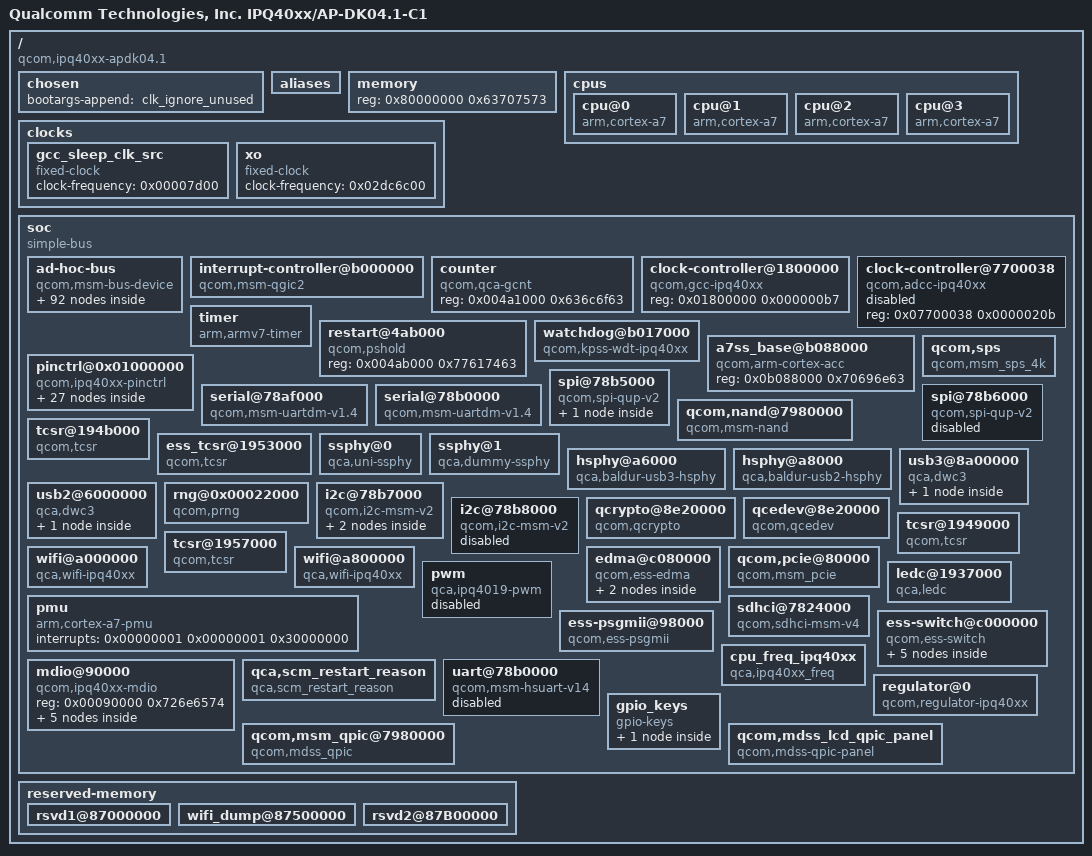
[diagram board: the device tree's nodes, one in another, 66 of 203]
/dts-v1/;
// magic:		0xd00dfeed
// totalsize:		0x93eb (37867)
// off_dt_struct:	0x38
// off_dt_strings:	0x8a74
// off_mem_rsvmap:	0x28
// version:		17
// last_comp_version:	16
// boot_cpuid_phys:	0x0
// size_dt_strings:	0x977
// size_dt_struct:	0x8a3c

/ {
    #address-cells = <0x00000001>;
    #size-cells = <0x00000001>;
    model = "Qualcomm Technologies, Inc. IPQ40xx/AP-DK04.1-C1";
    compatible = "qcom,ipq40xx-apdk04.1", "qcom,ipq40xx";
    interrupt-parent = <0x00000001>;
    chosen {
        bootargs-append = " clk_ignore_unused";
    };
    aliases {
        spi0 = "/soc/spi@78b5000";
        spi1 = "/soc/spi@78b6000";
        i2c0 = "/soc/i2c@78b7000";
        i2c1 = "/soc/i2c@78b8000";
        ethernet0 = "/soc/edma/gmac0";
        ethernet1 = "/soc/edma/gmac1";
    };
    memory {
        device_type = "memory";
        reg = <0x80000000 0x63707573>;
    };
    cpus {
        #address-cells = <0x00000001>;
        #size-cells = <0x00000000>;
        cpu@0 {
            device_type = "cpu";
            compatible = "arm,cortex-a7";
            enable-method = "qcom,arm-cortex-acc";
            reg = <0x00000000>;
            clocks = <0x00000002 0x0000009a>;
            clock-frequency = <0x00000000>;
        };
        cpu@1 {
            device_type = "cpu";
            compatible = "arm,cortex-a7";
            enable-method = "qcom,arm-cortex-acc";
            reg = <0x00000001>;
            clocks = <0x00000002 0x0000009a>;
            clock-frequency = <0x00000000>;
        };
        cpu@2 {
            device_type = "cpu";
            compatible = "arm,cortex-a7";
            enable-method = "qcom,arm-cortex-acc";
            reg = <0x00000002>;
            clocks = <0x00000002 0x0000009a>;
            clock-frequency = <0x00000000>;
        };
        cpu@3 {
            device_type = "cpu";
            compatible = "arm,cortex-a7";
            enable-method = "qcom,arm-cortex-acc";
            reg = <0x00000003>;
            clocks = <0x00000002 0x0000009a>;
            clock-frequency = <0x00000000>;
        };
    };
    clocks {
        gcc_sleep_clk_src {
            compatible = "fixed-clock";
            clock-frequency = <0x00007d00>;
            #clock-cells = <0x00000000>;
            linux,phandle = <0x00000047>;
            phandle = <0x00000047>;
        };
        xo {
            compatible = "fixed-clock";
            clock-frequency = <0x02dc6c00>;
            #clock-cells = <0x00000000>;
        };
    };
    soc {
        #address-cells = <0x00000001>;
        #size-cells = <0x00000001>;
        ranges;
        compatible = "simple-bus";
        ad-hoc-bus {
            compatible = "qcom,msm-bus-device";
            reg = <0x00580000 0x00000003 0x2d626173 0x00000000>;
            reg-names = "snoc-base", "pcnoc-base";
            fab-pcnoc {
                cell-id = <0x00001000>;
                label = "fab-pcnoc";
                qcom,fab-dev;
                qcom,base-name = "pcnoc-base";
                qcom,bypass-qos-prg;
                qcom,bus-type = <0x00000001>;
                qcom,qos-off = <0x00001000>;
                qcom,base-offset = <0x00000000>;
                clocks;
                linux,phandle = <0x00000004>;
                phandle = <0x00000004>;
            };
            fab-snoc {
                cell-id = <0x00000400>;
                label = "fab-snoc";
                qcom,fab-dev;
                qcom,base-name = "snoc-base";
                qcom,bypass-qos-prg;
                qcom,bus-type = <0x00000001>;
                qcom,qos-off = <0x00000080>;
                qcom,base-offset = <0x00000000>;
                clocks;
                linux,phandle = <0x00000031>;
                phandle = <0x00000031>;
            };
            mas-blsp-bam {
                cell-id = <0x0000006d>;
                label = "mas-blsp-bam";
                qcom,buswidth = <0x00000004>;
                qcom,ap-owned;
                qcom,connections = <0x00000003>;
                qcom,bus-dev = <0x00000004>;
                qcom,mas-rpm-id = <0x00000082>;
                qcom,blacklist = <0x00000005 0x00000009 0x0000000d 0x00000011 0x00000015 0x00000019 0x0000001d 0x00000021 0x00000025 0x00000029 0x6d61732d 0x00000003 0x00000003 0x75736232 0x00000004 0x00000000 0x00000199 0x000001a4 0x00000004 0x00000004 0x00000004 0x00000004 0x00000004 0x00000098 0x00000007 0x0000000b 0x0000000f 0x00000013 0x00000017 0x0000001b 0x0000001f 0x00000023 0x00000027 0x00000002 0x2d646d61 0x000000d6 0x000000de 0x30000000>;
            };
            mas-usb2-bam {
                cell-id = <0x0000006e>;
                label = "mas-usb2-bam";
                qcom,buswidth = <0x00000008>;
                qcom,ap-owned;
                qcom,qport = <0x0000000f>;
                qcom,qos-mode = "fixed";
                qcom,connections = <0x0000002b>;
                qcom,prio1 = <0x00000001>;
                qcom,prio0 = <0x00000001>;
                qcom,bus-dev = <0x00000004>;
                qcom,mas-rpm-id = <0x00000083>;
                qcom,blacklist = <0x00000005 0x00000009 0x0000000d 0x00000011 0x00000015 0x00000019 0x0000001d 0x00000021 0x00000025 0x00000029 0x6d61732d 0x00000003 0x00000003 0x61647373 0x00000004 0x00000000 0x0000015c 0x0000016d 0x0000017a 0x0000018a 0x00000008 0x0000000c 0x00000010 0x00000014 0x00000018 0x0000001c 0x00000020 0x00000024 0x00000028 0x00000001 0x31000000 0x00000070 0x6d61732d 0x00000003 0x00000003 0x00000004 0x00000004 0x00000004>;
            };
            mas-adss-dma0 {
                cell-id = <0x0000006f>;
                label = "mas-adss-dma0";
                qcom,buswidth = <0x00000004>;
                qcom,ap-owned;
                qcom,connections = <0x0000002c>;
                qcom,bus-dev = <0x00000004>;
                qcom,mas-rpm-id = <0x00000084>;
                qcom,blacklist = <0x00000005 0x00000009 0x0000000d 0x00000011 0x00000015 0x00000019 0x0000001d 0x00000021 0x00000025 0x00000029 0x6d61732d 0x00000003 0x00000003 0x61647373 0x00000004 0x00000000 0x0000015c 0x0000016d 0x0000017a 0x0000018a 0x00000008 0x0000000c 0x00000010 0x00000014 0x00000018 0x0000001c 0x00000020 0x00000024 0x00000028 0x00000001 0x32000000 0x00000071 0x6d61732d 0x00000003 0x00000003 0x00000004 0x00000004 0x00000004>;
            };
            mas-adss-dma1 {
                cell-id = <0x00000070>;
                label = "mas-adss-dma1";
                qcom,buswidth = <0x00000004>;
                qcom,ap-owned;
                qcom,connections = <0x0000002c>;
                qcom,bus-dev = <0x00000004>;
                qcom,mas-rpm-id = <0x00000085>;
                qcom,blacklist = <0x00000005 0x00000009 0x0000000d 0x00000011 0x00000015 0x00000019 0x0000001d 0x00000021 0x00000025 0x00000029 0x6d61732d 0x00000003 0x00000003 0x61647373 0x00000004 0x00000000 0x0000015c 0x0000016d 0x0000017a 0x0000018a 0x00000008 0x0000000c 0x00000010 0x00000014 0x00000018 0x0000001c 0x00000020 0x00000024 0x00000028 0x00000001 0x33000000 0x00000072 0x6d61732d 0x00000003 0x00000003 0x00000004 0x00000004 0x00000004>;
            };
            mas-adss-dma2 {
                cell-id = <0x00000071>;
                label = "mas-adss-dma2";
                qcom,buswidth = <0x00000004>;
                qcom,ap-owned;
                qcom,connections = <0x0000002c>;
                qcom,bus-dev = <0x00000004>;
                qcom,mas-rpm-id = <0x00000086>;
                qcom,blacklist = <0x00000005 0x00000009 0x0000000d 0x00000011 0x00000015 0x00000019 0x0000001d 0x00000021 0x00000025 0x00000029 0x6d61732d 0x00000003 0x00000003 0x61647373 0x00000004 0x00000000 0x0000015c 0x0000016d 0x0000017a 0x0000018a 0x00000008 0x0000000c 0x00000010 0x00000014 0x00000018 0x0000001c 0x00000020 0x00000024 0x00000028 0x00000001 0x00000000 0x00000073 0x6d61732d 0x00000003 0x00000003 0x00000004 0x00000004 0x00000004>;
            };
            mas-adss-dma3 {
                cell-id = <0x00000072>;
                label = "mas-adss-dma3";
                qcom,buswidth = <0x00000004>;
                qcom,ap-owned;
                qcom,connections = <0x0000002c>;
                qcom,bus-dev = <0x00000004>;
                qcom,mas-rpm-id = <0x00000087>;
                qcom,blacklist = <0x00000005 0x00000009 0x0000000d 0x00000011 0x00000015 0x00000019 0x0000001d 0x00000021 0x00000025 0x00000029 0x6d61732d 0x00000003 0x00000003 0x71706963 0x00000004 0x00000000 0x0000015c 0x0000016d 0x0000017a 0x0000018a 0x00000008 0x0000000c 0x00000010 0x00000014 0x00000018 0x0000001c 0x00000020 0x00000024 0x00000028 0x00000001 0x00000003 0x00000003 0x7370646d 0x00000140 0x0000014e 0x00000003 0x00000004 0x00000032>;
            };
            mas-qpic-bam {
                cell-id = <0x00000073>;
                label = "mas-qpic-bam";
                qcom,buswidth = <0x00000004>;
                qcom,ap-owned;
                qcom,connections = <0x00000003>;
                qcom,bus-dev = <0x00000004>;
                qcom,mas-rpm-id = <0x00000088>;
                qcom,blacklist = <0x00000005 0x00000009 0x0000000d 0x00000011 0x00000015 0x00000019 0x0000001d 0x00000021 0x00000025 0x00000029 0x6d61732d 0x00000004 0x00000009 0x00000000 0x00000004 0x00000003 0x00000003 0x00000003 0x00000003 0x00000006 0x0000000a 0x0000000e 0x00000012 0x00000016 0x0000001a 0x0000001e 0x00000022 0x00000026 0x0000002a 0x70636e6f 0x00000004 0x0000000e 0x632d6366 0x00000140 0x0000014e 0x00000026 0x00000004 0x00000054>;
            };
            mas-spdm {
                cell-id = <0x00000024>;
                label = "mas-spdm";
                qcom,buswidth = <0x00000004>;
                qcom,ap-owned;
                qcom,connections = <0x00000003>;
                qcom,bus-dev = <0x00000004>;
                qcom,mas-rpm-id = <0x00000032>;
                qcom,blacklist = <0x00000005 0x00000009 0x0000000d 0x00000011 0x00000015 0x00000019 0x0000001d 0x00000021 0x00000025 0x00000029 0x6d61732d 0x00000003 0x00000003 0x70636e6f 0x00000004 0x00000000 0x0000015c 0x0000016d 0x0000017a 0x6d61732d 0x000000d6 0x000000de 0x00000004 0x00000000 0x0000015c 0x00000004 0x00000004 0x00000001 0x00000000 0x00000074 0x6d61732d 0x00000003 0x00000003 0x00000004 0x00000006 0x00000003 0x00000003 0x00000003>;
            };
            mas-pcnoc-cfg {
                cell-id = <0x00000058>;
                label = "mas-pcnoc-cfg";
                qcom,buswidth = <0x00000004>;
                qcom,ap-owned;
                qcom,connections = <0x00000026>;
                qcom,bus-dev = <0x00000004>;
                qcom,mas-rpm-id = <0x00000054>;
            };
            mas-tic {
                cell-id = <0x0000004d>;
                label = "mas-tic";
                qcom,buswidth = <0x00000004>;
                qcom,ap-owned;
                qcom,connections = <0x0000002d 0x0000016d>;
                qcom,bus-dev = <0x00000004>;
                qcom,mas-rpm-id = <0x00000033>;
            };
            mas-sdcc-bam {
                cell-id = <0x00000074>;
                label = "mas-sdcc-bam";
                qcom,buswidth = <0x00000008>;
                qcom,ap-owned;
                qcom,qport = <0x0000000e>;
                qcom,qos-mode = "fixed";
                qcom,connections = <0x0000002b>;
                qcom,prio1 = <0x00000000>;
                qcom,prio0 = <0x00000000>;
                qcom,bus-dev = <0x00000004>;
                qcom,mas-rpm-id = <0x00000089>;
                qcom,blacklist = <0x00000005 0x00000009 0x0000000d 0x00000011 0x00000015 0x00000019 0x0000001d 0x00000021 0x00000025 0x00000029 0x6d61732d 0x00000003 0x00000003 0x736e6f63 0x00000004 0x00000000 0x00000199 0x000001a4 0x00000004 0x00000004 0x00000004 0x00000004 0x00000004 0x00000001 0x00000000 0x0000004c 0x6d61732d 0x00000003 0x00000003 0x00000008 0x00000003 0x00000003 0x00000002 0x2d736e6f 0x000000d6 0x000000de 0x63000000 0x00000010>;
            };
            mas-snoc-pcnoc {
                cell-id = <0x00002739>;
                label = "mas-snoc-pcnoc";
                qcom,buswidth = <0x00000004>;
                qcom,ap-owned;
                qcom,qport = <0x00000010>;
                qcom,qos-mode = "fixed";
                qcom,connections = <0x0000002d>;
                qcom,prio1 = <0x00000000>;
                qcom,prio0 = <0x00000000>;
                qcom,bus-dev = <0x00000004>;
                qcom,mas-rpm-id = <0x0000004d>;
            };
            mas-qdss-dap {
                cell-id = <0x0000004c>;
                label = "mas-qdss-dap";
                qcom,buswidth = <0x00000004>;
                qcom,ap-owned;
                qcom,connections = <0x0000002d 0x0000016d>;
                qcom,bus-dev = <0x00000004>;
                qcom,mas-rpm-id = <0x00000031>;
            };
            mas-ddrc-snoc {
                cell-id = <0x00000075>;
                label = "mas-ddrc-snoc";
                qcom,buswidth = <0x00000010>;
                qcom,ap-owned;
                qcom,connections = <0x0000002e 0x00000004 0x00000004>;
                qcom,bus-dev = <0x00000031>;
                qcom,mas-rpm-id = <0x0000008a>;
                qcom,blacklist = <0x00000032 0x6d61732d>;
            };
            mas-wss-0 {
                cell-id = <0x00000076>;
                label = "mas-wss-0";
                qcom,buswidth = <0x00000004>;
                qcom,ap-owned;
                qcom,qport = <0x0000001a>;
                qcom,qos-mode = "fixed";
                qcom,connections = <0x0000002e 0x000001b2>;
                qcom,prio1 = <0x00000000>;
                qcom,prio0 = <0x00000000>;
                qcom,bus-dev = <0x00000031>;
                qcom,mas-rpm-id = <0x0000008b>;
                qcom,blacklist = <0x00000034 0x00000037 0x00000001 0x00000003 0x00000003 0x7773732d 0x00000140>;
            };
            mas-wss-1 {
                cell-id = <0x00000077>;
                label = "mas-wss-1";
                qcom,buswidth = <0x00000004>;
                qcom,ap-owned;
                qcom,qport = <0x0000001b>;
                qcom,qos-mode = "fixed";
                qcom,connections = <0x0000002e 0x000001b2>;
                qcom,prio1 = <0x00000000>;
                qcom,prio0 = <0x00000000>;
                qcom,bus-dev = <0x00000031>;
                qcom,mas-rpm-id = <0x0000008c>;
                qcom,blacklist = <0x00000034 0x00000037 0x00000001 0x00000003 0x00000003 0x63727970 0x00000140>;
            };
            mas-crypto {
                cell-id = <0x0000002f>;
                label = "mas-crypto";
                qcom,buswidth = <0x00000008>;
                qcom,ap-owned;
                qcom,qport = <0x00000005>;
                qcom,qos-mode = "fixed";
                qcom,connections = <0x0000002e 0x00000004 0x00000004>;
                qcom,prio1 = <0x00000000>;
                qcom,prio0 = <0x00000000>;
                qcom,bus-dev = <0x00000031>;
                qcom,mas-rpm-id = <0x00000017>;
                qcom,blacklist = <0x00000034 0x0000003a 0x00000001 0x00000004 0x00000008 0x00000003 0x00000003>;
            };
            mas-ess {
                cell-id = <0x00000078>;
                label = "mas-ess";
                qcom,buswidth = <0x00000008>;
                qcom,ap-owned;
                qcom,qport = <0x0000002c>;
                qcom,qos-mode = "fixed";
                qcom,connections = <0x0000002e 0x000001b2>;
                qcom,prio1 = <0x00000000>;
                qcom,prio0 = <0x00000000>;
                qcom,bus-dev = <0x00000031>;
                qcom,mas-rpm-id = <0x0000008d>;
                qcom,blacklist = <0x00000034 0x0000003a 0x00000033 0x70636965 0x000000d6 0x000000de 0x00000003 0x00000003 0x00000004>;
            };
            mas-pcie {
                cell-id = <0x0000002d>;
                label = "mas-pcie";
                qcom,buswidth = <0x00000008>;
                qcom,ap-owned;
                qcom,qport = <0x00000006>;
                qcom,qos-mode = "fixed";
                qcom,connections = <0x0000002e 0x000001b2>;
                qcom,prio1 = <0x00000000>;
                qcom,prio0 = <0x00000000>;
                qcom,bus-dev = <0x00000031>;
                qcom,mas-rpm-id = <0x0000008e>;
                qcom,blacklist = <0x00000034 0x00000036 0x00000002 0x00000000 0x0000003d 0x6d61732d 0x00000004 0x00000000>;
            };
            mas-usb3 {
                cell-id = <0x0000003d>;
                label = "mas-usb3";
                qcom,buswidth = <0x00000008>;
                qcom,ap-owned;
                qcom,qport = <0x00000007>;
                qcom,qos-mode = "fixed";
                qcom,connections = <0x0000002e 0x000001b2>;
                qcom,prio1 = <0x00000000>;
                qcom,prio0 = <0x00000000>;
                qcom,bus-dev = <0x00000031>;
                qcom,mas-rpm-id = <0x00000020>;
                qcom,blacklist = <0x00000034 0x0000003a 0x00000033 0x71647373 0x00000004 0x0000000d 0x2d657472 0x00000140 0x0000014e>;
            };
            mas-qdss-etr {
                cell-id = <0x0000003c>;
                label = "mas-qdss-etr";
                qcom,buswidth = <0x00000008>;
                qcom,ap-owned;
                qcom,qport = <0x00000220>;
                qcom,qos-mode = "fixed";
                qcom,connections = <0x0000003b>;
                qcom,prio1 = <0x00000000>;
                qcom,prio0 = <0x00000000>;
                qcom,bus-dev = <0x00000031>;
                qcom,mas-rpm-id = <0x0000001f>;
                qcom,blacklist = <0x00000034 0x0000003a 0x00000033 0x71647373 0x00000004 0x00000010 0x2d62616d 0x00000140 0x0000014e>;
            };
            mas-qdss-bamndp {
                cell-id = <0x00000079>;
                label = "mas-qdss-bamndp";
                qcom,buswidth = <0x00000004>;
                qcom,ap-owned;
                qcom,qport = <0x00000240>;
                qcom,qos-mode = "fixed";
                qcom,connections = <0x0000003b>;
                qcom,prio1 = <0x00000000>;
                qcom,prio0 = <0x00000000>;
                qcom,bus-dev = <0x00000031>;
                qcom,mas-rpm-id = <0x0000008f>;
                qcom,blacklist = <0x00000034 0x0000003a 0x00000033 0x70636e6f 0x00000004 0x0000000f 0x632d736e 0x00000140 0x0000014e>;
            };
            mas-pcnoc-snoc {
                cell-id = <0x0000271a>;
                label = "mas-pcnoc-snoc";
                qcom,buswidth = <0x00000004>;
                qcom,ap-owned;
                qcom,qport = <0x00000180>;
                qcom,qos-mode = "fixed";
                qcom,connections = <0x0000002e 0x00000004 0x00000004>;
                qcom,prio1 = <0x00000000>;
                qcom,prio0 = <0x00000000>;
                qcom,bus-dev = <0x00000031>;
                qcom,mas-rpm-id = <0x0000001d>;
                qcom,blacklist = <0x00000033>;
            };
            mas-snoc-cfg {
                cell-id = <0x0000007a>;
                label = "mas-snoc-cfg";
                qcom,buswidth = <0x00000004>;
                qcom,ap-owned;
                qcom,connections = <0x00000033>;
                qcom,bus-dev = <0x00000031>;
                qcom,mas-rpm-id = <0x00000090>;
            };
            pcnoc-m-0 {
                cell-id = <0x0000271e>;
                label = "pcnoc-m-0";
                qcom,buswidth = <0x00000004>;
                qcom,ap-owned;
                qcom,qport = <0x0000000c>;
                qcom,qos-mode = "fixed";
                qcom,connections = <0x0000002b>;
                qcom,prio1 = <0x00000001>;
                qcom,prio0 = <0x00000001>;
                qcom,bus-dev = <0x00000004>;
                qcom,mas-rpm-id = <0x00000057>;
                qcom,slv-rpm-id = <0x00000074>;
                linux,phandle = <0x00000003>;
                phandle = <0x00000003>;
            };
            pcnoc-m-1 {
                cell-id = <0x0000271f>;
                label = "pcnoc-m-1";
                qcom,buswidth = <0x00000004>;
                qcom,ap-owned;
                qcom,qport = <0x0000000d>;
                qcom,qos-mode = "fixed";
                qcom,connections = <0x0000002b>;
                qcom,prio1 = <0x00000001>;
                qcom,prio0 = <0x00000001>;
                qcom,bus-dev = <0x00000004>;
                qcom,mas-rpm-id = <0x00000058>;
                qcom,slv-rpm-id = <0x00000075>;
                linux,phandle = <0x0000002c>;
                phandle = <0x0000002c>;
            };
            pcnoc-int-0 {
                cell-id = <0x0000271c>;
                label = "pcnoc-int-0";
                qcom,buswidth = <0x00000008>;
                qcom,ap-owned;
                qcom,connections = <0x0000003c 0x00000040 0x00000044 0x0000016d 0x0000017a 0x000001c8 0x000000b7 0x000000bd 0x70636e6f 0x00000004>;
                qcom,bus-dev = <0x00000004>;
                qcom,mas-rpm-id = <0x00000055>;
                qcom,slv-rpm-id = <0x00000072>;
                linux,phandle = <0x0000002d>;
                phandle = <0x0000002d>;
            };
            pcnoc-s-0 {
                cell-id = <0x00002722>;
                label = "pcnoc-s-0";
                qcom,buswidth = <0x00000004>;
                qcom,ap-owned;
                qcom,connections = <0x00000022 0x00000003 0x00000003 0x00000003>;
                qcom,bus-dev = <0x00000004>;
                qcom,mas-rpm-id = <0x00000059>;
                qcom,slv-rpm-id = <0x00000076>;
                linux,phandle = <0x0000003e>;
                phandle = <0x0000003e>;
            };
            pcnoc-s-1 {
                cell-id = <0x00002723>;
                label = "pcnoc-s-1";
                qcom,buswidth = <0x00000004>;
                qcom,ap-owned;
                qcom,connections = <0x00000019 0x00000004 0x00000004>;
                qcom,bus-dev = <0x00000004>;
                qcom,mas-rpm-id = <0x0000005a>;
                qcom,slv-rpm-id = <0x00000077>;
                linux,phandle = <0x0000003c>;
                phandle = <0x0000003c>;
            };
            pcnoc-s-2 {
                cell-id = <0x00002724>;
                label = "pcnoc-s-2";
                qcom,buswidth = <0x00000004>;
                qcom,ap-owned;
                qcom,connections = <0x0000001c 0x00000003 0x00000003 0x00000003>;
                qcom,bus-dev = <0x00000004>;
                qcom,mas-rpm-id = <0x0000005b>;
                qcom,slv-rpm-id = <0x00000078>;
                linux,phandle = <0x0000003d>;
                phandle = <0x0000003d>;
            };
            pcnoc-s-3 {
                cell-id = <0x00002725>;
                label = "pcnoc-s-3";
                qcom,buswidth = <0x00000004>;
                qcom,ap-owned;
                qcom,connections = <0x00000013 0x00000003 0x00000003 0x00000003>;
                qcom,bus-dev = <0x00000004>;
                qcom,mas-rpm-id = <0x0000005c>;
                qcom,slv-rpm-id = <0x00000079>;
                linux,phandle = <0x00000045>;
                phandle = <0x00000045>;
            };
            pcnoc-s-4 {
                cell-id = <0x00002726>;
                label = "pcnoc-s-4";
                qcom,buswidth = <0x00000004>;
                qcom,ap-owned;
                qcom,connections = <0x00000007 0x00000004 0x00000004>;
                qcom,bus-dev = <0x00000004>;
                qcom,mas-rpm-id = <0x0000005d>;
                qcom,slv-rpm-id = <0x0000007a>;
                linux,phandle = <0x0000003f>;
                phandle = <0x0000003f>;
            };
            pcnoc-s-5 {
                cell-id = <0x0000273f>;
                label = "pcnoc-s-5";
                qcom,buswidth = <0x00000004>;
                qcom,ap-owned;
                qcom,connections = <0x00000020 0x00000003 0x00000003 0x00000003>;
                qcom,bus-dev = <0x00000004>;
                qcom,mas-rpm-id = <0x00000081>;
                qcom,slv-rpm-id = <0x000000bd>;
                linux,phandle = <0x00000040>;
                phandle = <0x00000040>;
            };
            pcnoc-s-6 {
                cell-id = <0x00002740>;
                label = "pcnoc-s-6";
                qcom,buswidth = <0x00000004>;
                qcom,ap-owned;
                qcom,connections = <0x0000000b 0x0000000a 0x00000004 0x0000005e 0x0000007b>;
                qcom,bus-dev = <0x00000004>;
                qcom,mas-rpm-id = <0x0000005e>;
                qcom,slv-rpm-id = <0x0000007b>;
                linux,phandle = <0x00000041>;
                phandle = <0x00000041>;
            };
            pcnoc-s-7 {
                cell-id = <0x00002752>;
                label = "pcnoc-s-7";
                qcom,buswidth = <0x00000004>;
                qcom,ap-owned;
                qcom,connections = <0x0000000f 0x00000004 0x00000004>;
                qcom,bus-dev = <0x00000004>;
                qcom,mas-rpm-id = <0x0000005f>;
                qcom,slv-rpm-id = <0x0000007c>;
                linux,phandle = <0x00000042>;
                phandle = <0x00000042>;
            };
            pcnoc-s-8 {
                cell-id = <0x00002727>;
                label = "pcnoc-s-8";
                qcom,buswidth = <0x00000004>;
                qcom,ap-owned;
                qcom,connections = <0x00000029 0x00000004 0x00000004>;
                qcom,bus-dev = <0x00000004>;
                qcom,mas-rpm-id = <0x00000060>;
                qcom,slv-rpm-id = <0x0000007d>;
                linux,phandle = <0x00000043>;
                phandle = <0x00000043>;
            };
            pcnoc-s-9 {
                cell-id = <0x00002728>;
                label = "pcnoc-s-9";
                qcom,buswidth = <0x00000004>;
                qcom,ap-owned;
                qcom,connections = <0x00000009 0x00000003 0x00000003 0x00000003>;
                qcom,bus-dev = <0x00000004>;
                qcom,mas-rpm-id = <0x00000061>;
                qcom,slv-rpm-id = <0x0000007e>;
                linux,phandle = <0x00000044>;
                phandle = <0x00000044>;
            };
            snoc-int-0 {
                cell-id = <0x00002714>;
                label = "snoc-int-0";
                qcom,buswidth = <0x00000008>;
                qcom,ap-owned;
                qcom,connections = <0x00000046 0x0000016d>;
                qcom,bus-dev = <0x00000031>;
                qcom,mas-rpm-id = <0x00000063>;
                qcom,slv-rpm-id = <0x00000082>;
                linux,phandle = <0x0000002e>;
                phandle = <0x0000002e>;
            };
            snoc-int-1 {
                cell-id = <0x00002715>;
                label = "snoc-int-1";
                qcom,buswidth = <0x00000008>;
                qcom,ap-owned;
                qcom,connections = <0x00000038 0x00000036 0x0000016d 0x0000017a 0x000001c8 0x000000b7>;
                qcom,bus-dev = <0x00000031>;
                qcom,mas-rpm-id = <0x00000064>;
                qcom,slv-rpm-id = <0x00000083>;
                linux,phandle = <0x0000002f>;
                phandle = <0x0000002f>;
            };
            qdss-int {
                cell-id = <0x00002719>;
                label = "qdss-int";
                qcom,buswidth = <0x00000008>;
                qcom,ap-owned;
                qcom,connections = <0x0000002e 0x0000016d>;
                qcom,bus-dev = <0x00000031>;
                qcom,mas-rpm-id = <0x00000062>;
                qcom,slv-rpm-id = <0x00000080>;
                linux,phandle = <0x0000003b>;
                phandle = <0x0000003b>;
            };
            slv-clk-ctl {
                cell-id = <0x0000026c>;
                label = "slv-clk-ctl";
                qcom,buswidth = <0x00000004>;
                qcom,ap-owned;
                qcom,bus-dev = <0x00000004>;
                qcom,slv-rpm-id = <0x0000002f>;
                linux,phandle = <0x00000022>;
                phandle = <0x00000022>;
            };
            slv-security {
                cell-id = <0x0000026e>;
                label = "slv-security";
                qcom,buswidth = <0x00000004>;
                qcom,ap-owned;
                qcom,bus-dev = <0x00000004>;
                qcom,slv-rpm-id = <0x00000031>;
                linux,phandle = <0x0000001b>;
                phandle = <0x0000001b>;
            };
            slv-tcsr {
                cell-id = <0x0000026f>;
                label = "slv-tcsr";
                qcom,buswidth = <0x00000004>;
                qcom,ap-owned;
                qcom,bus-dev = <0x00000004>;
                qcom,slv-rpm-id = <0x00000032>;
                linux,phandle = <0x00000005>;
                phandle = <0x00000005>;
            };
            slv-tlmm {
                cell-id = <0x00000270>;
                label = "slv-tlmm";
                qcom,buswidth = <0x00000004>;
                qcom,ap-owned;
                qcom,bus-dev = <0x00000004>;
                qcom,slv-rpm-id = <0x00000033>;
                linux,phandle = <0x00000017>;
                phandle = <0x00000017>;
            };
            slv-imem-cfg {
                cell-id = <0x00000273>;
                label = "slv-imem-cfg";
                qcom,buswidth = <0x00000004>;
                qcom,ap-owned;
                qcom,bus-dev = <0x00000004>;
                qcom,slv-rpm-id = <0x00000036>;
                linux,phandle = <0x00000010>;
                phandle = <0x00000010>;
            };
            slv-prng {
                cell-id = <0x0000026a>;
                label = "slv-prng";
                qcom,buswidth = <0x00000004>;
                qcom,ap-owned;
                qcom,bus-dev = <0x00000004>;
                qcom,slv-rpm-id = <0x0000002c>;
                linux,phandle = <0x00000012>;
                phandle = <0x00000012>;
            };
            slv-prng-apu-cfg {
                cell-id = <0x000002cc>;
                label = "slv-prng-apu-cfg";
                qcom,buswidth = <0x00000004>;
                qcom,ap-owned;
                qcom,bus-dev = <0x00000004>;
                qcom,slv-rpm-id = <0x000000be>;
                linux,phandle = <0x00000019>;
                phandle = <0x00000019>;
            };
            slv-boot-rom {
                cell-id = <0x00000276>;
                label = "slv-boot-rom";
                qcom,buswidth = <0x00000004>;
                qcom,ap-owned;
                qcom,bus-dev = <0x00000004>;
                qcom,slv-rpm-id = <0x00000039>;
                linux,phandle = <0x0000001a>;
                phandle = <0x0000001a>;
            };
            slv-spdm {
                cell-id = <0x00000279>;
                label = "slv-spdm";
                qcom,buswidth = <0x00000004>;
                qcom,ap-owned;
                qcom,bus-dev = <0x00000004>;
                qcom,slv-rpm-id = <0x0000003c>;
                linux,phandle = <0x0000001c>;
                phandle = <0x0000001c>;
            };
            slv-pcnoc-cfg {
                cell-id = <0x00000281>;
                label = "slv-pcnoc-cfg";
                qcom,buswidth = <0x00000004>;
                qcom,ap-owned;
                qcom,bus-dev = <0x00000004>;
                qcom,slv-rpm-id = <0x00000045>;
                linux,phandle = <0x0000000e>;
                phandle = <0x0000000e>;
            };
            slv-pcnoc-mpu-cfg {
                cell-id = <0x000002cd>;
                label = "slv-pcnoc-mpu-cfg";
                qcom,buswidth = <0x00000004>;
                qcom,ap-owned;
                qcom,bus-dev = <0x00000004>;
                qcom,slv-rpm-id = <0x000000bf>;
                linux,phandle = <0x0000001d>;
                phandle = <0x0000001d>;
            };
            slv-gcnt {
                cell-id = <0x000002ce>;
                label = "slv-gcnt";
                qcom,buswidth = <0x00000004>;
                qcom,ap-owned;
                qcom,bus-dev = <0x00000004>;
                qcom,slv-rpm-id = <0x000000c0>;
                linux,phandle = <0x00000016>;
                phandle = <0x00000016>;
            };
            slv-qdss-cfg {
                cell-id = <0x0000027b>;
                label = "slv-qdss-cfg";
                qcom,buswidth = <0x00000004>;
                qcom,ap-owned;
                qcom,bus-dev = <0x00000004>;
                qcom,slv-rpm-id = <0x0000003f>;
                linux,phandle = <0x00000013>;
                phandle = <0x00000013>;
            };
            slv-snoc-cfg {
                cell-id = <0x00000282>;
                label = "slv-snoc-cfg";
                qcom,buswidth = <0x00000004>;
                qcom,ap-owned;
                qcom,bus-dev = <0x00000004>;
                qcom,slv-rpm-id = <0x00000046>;
                linux,phandle = <0x0000002a>;
                phandle = <0x0000002a>;
            };
            slv-snoc-mpu-cfg {
                cell-id = <0x0000027e>;
                label = "slv-snoc-mpu-cfg";
                qcom,buswidth = <0x00000004>;
                qcom,ap-owned;
                qcom,bus-dev = <0x00000004>;
                qcom,slv-rpm-id = <0x00000043>;
                linux,phandle = <0x00000027>;
                phandle = <0x00000027>;
            };
            slv-adss-cfg {
                cell-id = <0x000002cf>;
                label = "slv-adss-cfg";
                qcom,buswidth = <0x00000004>;
                qcom,ap-owned;
                qcom,bus-dev = <0x00000004>;
                qcom,slv-rpm-id = <0x000000c1>;
                linux,phandle = <0x00000007>;
                phandle = <0x00000007>;
            };
            slv-adss-apu {
                cell-id = <0x000002d0>;
                label = "slv-adss-apu";
                qcom,buswidth = <0x00000004>;
                qcom,ap-owned;
                qcom,bus-dev = <0x00000004>;
                qcom,slv-rpm-id = <0x000000c2>;
                linux,phandle = <0x00000023>;
                phandle = <0x00000023>;
            };
            slv-adss-vmidmt-cfg {
                cell-id = <0x000002d0>;
                label = "slv-adss-vmidmt-cfg";
                qcom,buswidth = <0x00000004>;
                qcom,ap-owned;
                qcom,bus-dev = <0x00000004>;
                qcom,slv-rpm-id = <0x000000c3>;
                linux,phandle = <0x00000021>;
                phandle = <0x00000021>;
            };
            slv-qhss-apu-cfg {
                cell-id = <0x000002d1>;
                label = "slv-qhss-apu-cfg";
                qcom,buswidth = <0x00000004>;
                qcom,ap-owned;
                qcom,bus-dev = <0x00000004>;
                qcom,slv-rpm-id = <0x000000c4>;
                linux,phandle = <0x00000020>;
                phandle = <0x00000020>;
            };
            slv-mdio {
                cell-id = <0x000002d2>;
                label = "slv-mdio";
                qcom,buswidth = <0x00000004>;
                qcom,ap-owned;
                qcom,bus-dev = <0x00000004>;
                qcom,slv-rpm-id = <0x000000c5>;
                linux,phandle = <0x00000006>;
                phandle = <0x00000006>;
            };
            slv-fephy-cfg {
                cell-id = <0x000002d3>;
                label = "slv-fephy-cfg";
                qcom,buswidth = <0x00000004>;
                qcom,ap-owned;
                qcom,bus-dev = <0x00000004>;
                qcom,slv-rpm-id = <0x000000c6>;
                linux,phandle = <0x00000008>;
                phandle = <0x00000008>;
            };
            slv-srif {
                cell-id = <0x000002d4>;
                label = "slv-srif";
                qcom,buswidth = <0x00000004>;
                qcom,ap-owned;
                qcom,bus-dev = <0x00000004>;
                qcom,slv-rpm-id = <0x000000c7>;
                linux,phandle = <0x00000011>;
                phandle = <0x00000011>;
            };
            slv-ddrc-cfg {
                cell-id = <0x000002db>;
                label = "slv-ddrc-cfg";
                qcom,buswidth = <0x00000004>;
                qcom,ap-owned;
                qcom,bus-dev = <0x00000004>;
                qcom,slv-rpm-id = <0x000000c8>;
                linux,phandle = <0x0000000d>;
                phandle = <0x0000000d>;
            };
            slv-ddrc-apu-cfg {
                cell-id = <0x000002dc>;
                label = "slv-ddrc-apu-cfg";
                qcom,buswidth = <0x00000004>;
                qcom,ap-owned;
                qcom,bus-dev = <0x00000004>;
                qcom,slv-rpm-id = <0x000000c9>;
                linux,phandle = <0x00000015>;
                phandle = <0x00000015>;
            };
            slv-ddrc-mpu0-cfg {
                cell-id = <0x000002dd>;
                label = "slv-ddrc-mpu0-cfg";
                qcom,buswidth = <0x00000004>;
                qcom,ap-owned;
                qcom,bus-dev = <0x00000004>;
                qcom,slv-rpm-id = <0x000000ca>;
                linux,phandle = <0x0000000b>;
                phandle = <0x0000000b>;
            };
            slv-ddrc-mpu1-cfg {
                cell-id = <0x000002de>;
                label = "slv-ddrc-mpu1-cfg";
                qcom,buswidth = <0x00000004>;
                qcom,ap-owned;
                qcom,bus-dev = <0x00000004>;
                qcom,slv-rpm-id = <0x000000cb>;
                linux,phandle = <0x0000000a>;
                phandle = <0x0000000a>;
            };
            slv-ddrc-mpu2-cfg {
                cell-id = <0x000002de>;
                label = "slv-ddrc-mpu2-cfg";
                qcom,buswidth = <0x00000004>;
                qcom,ap-owned;
                qcom,bus-dev = <0x00000004>;
                qcom,slv-rpm-id = <0x000000d2>;
                linux,phandle = <0x0000001e>;
                phandle = <0x0000001e>;
            };
            slv-ess-vmidmt-cfg {
                cell-id = <0x000002df>;
                label = "slv-ess-vmidmt-cfg";
                qcom,buswidth = <0x00000004>;
                qcom,ap-owned;
                qcom,bus-dev = <0x00000004>;
                qcom,slv-rpm-id = <0x000000d3>;
                linux,phandle = <0x0000001f>;
                phandle = <0x0000001f>;
            };
            slv-ess-apu-cfg {
                cell-id = <0x000002e0>;
                label = "slv-ess-apu-cfg";
                qcom,buswidth = <0x00000004>;
                qcom,ap-owned;
                qcom,bus-dev = <0x00000004>;
                qcom,slv-rpm-id = <0x000000d4>;
                linux,phandle = <0x0000000f>;
                phandle = <0x0000000f>;
            };
            slv-usb2-cfg {
                cell-id = <0x000002e1>;
                label = "slv-usb2-cfg";
                qcom,buswidth = <0x00000004>;
                qcom,ap-owned;
                qcom,bus-dev = <0x00000004>;
                qcom,slv-rpm-id = <0x000000d5>;
                linux,phandle = <0x00000025>;
                phandle = <0x00000025>;
            };
            slv-blsp-cfg {
                cell-id = <0x000002e2>;
                label = "slv-blsp-cfg";
                qcom,buswidth = <0x00000004>;
                qcom,ap-owned;
                qcom,bus-dev = <0x00000004>;
                qcom,slv-rpm-id = <0x000000d6>;
                linux,phandle = <0x00000024>;
                phandle = <0x00000024>;
            };
            slv-qpic-cfg {
                cell-id = <0x000002e3>;
                label = "slv-qpic-cfg";
                qcom,buswidth = <0x00000004>;
                qcom,ap-owned;
                qcom,bus-dev = <0x00000004>;
                qcom,slv-rpm-id = <0x000000d7>;
                linux,phandle = <0x0000000c>;
                phandle = <0x0000000c>;
            };
            slv-sdcc-cfg {
                cell-id = <0x000002e4>;
                label = "slv-sdcc-cfg";
                qcom,buswidth = <0x00000004>;
                qcom,ap-owned;
                qcom,bus-dev = <0x00000004>;
                qcom,slv-rpm-id = <0x000000d8>;
                linux,phandle = <0x00000029>;
                phandle = <0x00000029>;
            };
            slv-wss0-vmidmt-cfg {
                cell-id = <0x000002e5>;
                label = "slv-wss0-vmidmt-cfg";
                qcom,buswidth = <0x00000004>;
                qcom,ap-owned;
                qcom,bus-dev = <0x00000004>;
                qcom,slv-rpm-id = <0x000000d9>;
                linux,phandle = <0x00000018>;
                phandle = <0x00000018>;
            };
            slv-wss0-apu-cfg {
                cell-id = <0x000002e6>;
                label = "slv-wss0-apu-cfg";
                qcom,buswidth = <0x00000004>;
                qcom,ap-owned;
                qcom,bus-dev = <0x00000004>;
                qcom,slv-rpm-id = <0x000000da>;
                linux,phandle = <0x00000014>;
                phandle = <0x00000014>;
            };
            slv-wss1-vmidmt-cfg {
                cell-id = <0x000002e7>;
                label = "slv-wss1-vmidmt-cfg";
                qcom,buswidth = <0x00000004>;
                qcom,ap-owned;
                qcom,bus-dev = <0x00000004>;
                qcom,slv-rpm-id = <0x000000db>;
                linux,phandle = <0x00000028>;
                phandle = <0x00000028>;
            };
            slv-wss1-apu-cfg {
                cell-id = <0x000002e8>;
                label = "slv-wss1-apu-cfg";
                qcom,buswidth = <0x00000004>;
                qcom,ap-owned;
                qcom,bus-dev = <0x00000004>;
                qcom,slv-rpm-id = <0x000000dc>;
                linux,phandle = <0x00000009>;
                phandle = <0x00000009>;
            };
            slv-pcnoc-snoc {
                cell-id = <0x0000271b>;
                label = "slv-pcnoc-snoc";
                qcom,buswidth = <0x00000004>;
                qcom,ap-owned;
                qcom,bus-dev = <0x00000004>;
                qcom,slv-rpm-id = <0x0000002d>;
                linux,phandle = <0x0000002b>;
                phandle = <0x0000002b>;
            };
            slv-srvc-pcnoc {
                cell-id = <0x000002e9>;
                label = "slv-srvc-pcnoc";
                qcom,buswidth = <0x00000004>;
                qcom,ap-owned;
                qcom,bus-dev = <0x00000004>;
                qcom,slv-rpm-id = <0x000000dd>;
                linux,phandle = <0x00000026>;
                phandle = <0x00000026>;
            };
            slv-snoc-ddrc-m1 {
                cell-id = <0x000002ea>;
                label = "slv-snoc-ddrc-m1";
                qcom,buswidth = <0x00000008>;
                qcom,ap-owned;
                qcom,bus-dev = <0x00000031>;
                qcom,slv-rpm-id = <0x000000de>;
                linux,phandle = <0x00000032>;
                phandle = <0x00000032>;
            };
            slv-a7ss {
                cell-id = <0x000002eb>;
                label = "slv-a7ss";
                qcom,buswidth = <0x00000004>;
                qcom,ap-owned;
                qcom,bus-dev = <0x00000031>;
                qcom,slv-rpm-id = <0x000000df>;
                linux,phandle = <0x00000039>;
                phandle = <0x00000039>;
            };
            slv-ocimem {
                cell-id = <0x00000249>;
                label = "slv-ocimem";
                qcom,buswidth = <0x00000008>;
                qcom,ap-owned;
                qcom,bus-dev = <0x00000031>;
                qcom,slv-rpm-id = <0x0000001a>;
                linux,phandle = <0x00000046>;
                phandle = <0x00000046>;
            };
            slv-wss0-cfg {
                cell-id = <0x000002ec>;
                label = "slv-wss0-cfg";
                qcom,buswidth = <0x00000004>;
                qcom,ap-owned;
                qcom,bus-dev = <0x00000031>;
                qcom,slv-rpm-id = <0x000000e0>;
                linux,phandle = <0x00000037>;
                phandle = <0x00000037>;
            };
            slv-wss1-cfg {
                cell-id = <0x000002ed>;
                label = "slv-wss1-cfg";
                qcom,buswidth = <0x00000004>;
                qcom,ap-owned;
                qcom,bus-dev = <0x00000031>;
                qcom,slv-rpm-id = <0x000000e1>;
                linux,phandle = <0x00000036>;
                phandle = <0x00000036>;
            };
            slv-pcie {
                cell-id = <0x000002ee>;
                label = "slv-pcie";
                qcom,buswidth = <0x00000008>;
                qcom,ap-owned;
                qcom,bus-dev = <0x00000031>;
                qcom,slv-rpm-id = <0x000000e2>;
                linux,phandle = <0x00000030>;
                phandle = <0x00000030>;
            };
            slv-usb3-cfg {
                cell-id = <0x000002ef>;
                label = "slv-usb3-cfg";
                qcom,buswidth = <0x00000004>;
                qcom,ap-owned;
                qcom,bus-dev = <0x00000031>;
                qcom,slv-rpm-id = <0x000000e3>;
                linux,phandle = <0x00000034>;
                phandle = <0x00000034>;
            };
            slv-crypto-cfg {
                cell-id = <0x000002f0>;
                label = "slv-crypto-cfg";
                qcom,buswidth = <0x00000004>;
                qcom,ap-owned;
                qcom,bus-dev = <0x00000031>;
                qcom,slv-rpm-id = <0x000000e4>;
                linux,phandle = <0x00000038>;
                phandle = <0x00000038>;
            };
            slv-ess-cfg {
                cell-id = <0x000002f1>;
                label = "slv-ess-cfg";
                qcom,buswidth = <0x00000004>;
                qcom,ap-owned;
                qcom,bus-dev = <0x00000031>;
                qcom,slv-rpm-id = <0x000000e5>;
                linux,phandle = <0x00000035>;
                phandle = <0x00000035>;
            };
            slv-qdss-stm {
                cell-id = <0x0000024c>;
                label = "slv-qdss-stm";
                qcom,buswidth = <0x00000004>;
                qcom,ap-owned;
                qcom,bus-dev = <0x00000031>;
                qcom,slv-rpm-id = <0x0000001e>;
                linux,phandle = <0x0000003a>;
                phandle = <0x0000003a>;
            };
            slv-srvc-snoc {
                cell-id = <0x000002f2>;
                label = "slv-srvc-snoc";
                qcom,buswidth = <0x00000008>;
                qcom,ap-owned;
                qcom,bus-dev = <0x00000031>;
                qcom,slv-rpm-id = <0x000000e6>;
                linux,phandle = <0x00000033>;
                phandle = <0x00000033>;
            };
        };
        interrupt-controller@b000000 {
            compatible = "qcom,msm-qgic2";
            interrupt-controller;
            #interrupt-cells = <0x00000003>;
            reg = <0x0b000000 0x00000003 0x00000003 0x00000002>;
            linux,phandle = <0x00000001>;
            phandle = <0x00000001>;
        };
        counter {
            compatible = "qcom,qca-gcnt";
            reg = <0x004a1000 0x636c6f63>;
        };
        clock-controller@1800000 {
            compatible = "qcom,gcc-ipq40xx";
            #clock-cells = <0x00000001>;
            #reset-cells = <0x00000001>;
            reg = <0x01800000 0x000000b7>;
            linux,phandle = <0x00000002>;
            phandle = <0x00000002>;
        };
        clock-controller@7700038 {
            compatible = "qcom,adcc-ipq40xx";
            #clock-cells = <0x00000001>;
            #reset-cells = <0x00000001>;
            reg = <0x07700038 0x0000020b>;
            status = "disabled";
        };
        timer {
            compatible = "arm,armv7-timer";
            interrupts = <0x00000001 0x00000003 0x00000f08 0x00000003 0x00000002 0x34616230 0x00000021 0x00000003 0x00000004 0x68646f67 0x00000003 0x2c6b7073>;
            clock-frequency = <0x02dc6c00>;
        };
        restart@4ab000 {
            compatible = "qcom,pshold";
            reg = <0x004ab000 0x77617463>;
        };
        watchdog@b017000 {
            compatible = "qcom,kpss-wdt-ipq40xx";
            reg = <0x0b017000 0x0000021d>;
            interrupt-names = "bark_irq";
            interrupts = <0x00000000 0x00000004 0x00000004>;
            clocks = <0x00000047>;
            timeout-sec = <0x0000000a>;
            wdt_res = <0x00000004>;
            wdt_en = <0x00000008>;
            wdt_bark_time = <0x00000010>;
            wdt_bite_time = <0x00000014>;
            status = "ok";
        };
        a7ss_base@b088000 {
            compatible = "qcom,arm-cortex-acc";
            reg = <0x0b088000 0x70696e63>;
        };
        pinctrl@0x01000000 {
            compatible = "qcom,ipq40xx-pinctrl";
            reg = <0x01000000 0x00000264>;
            gpio-controller;
            #gpio-cells = <0x00000002>;
            interrupt-controller;
            #interrupt-cells = <0x00000002>;
            interrupts = <0x00000000 0x00000004 0x00000004>;
            linux,phandle = <0x00000051>;
            phandle = <0x00000051>;
            serial0_pinmux {
                linux,phandle = <0x00000048>;
                phandle = <0x00000048>;
                mux {
                    pins = "gpio16", "gpio17";
                    function = "blsp_uart0";
                    bias-disable;
                };
            };
            led0_pinmux {
                linux,phandle = <0x00000052>;
                phandle = <0x00000052>;
                mux_1 {
                    pins = "gpio36";
                    function = "led0";
                    bias-pull-down;
                };
                mux_2 {
                    pins = "gpio40";
                    function = "led4";
                    bias-pull-down;
                };
            };
            serial1_pinmux {
                linux,phandle = <0x00000049>;
                phandle = <0x00000049>;
                mux {
                    pins = "gpio8", "gpio9";
                    function = "blsp_uart1";
                    bias-disable;
                };
            };
            uart1_pinmux {
                linux,phandle = <0x00000056>;
                phandle = <0x00000056>;
                mux {
                    pins = "gpio8", "gpio9", "gpio10", "gpio11";
                    function = "blsp_uart1";
                    bias-disable;
                };
            };
            spi_0_pinmux {
                linux,phandle = <0x0000004a>;
                phandle = <0x0000004a>;
                mux {
                    pins = "gpio12", "gpio13", "gpio14", "gpio15";
                    function = "blsp_spi0";
                    bias-disable;
                };
            };
            i2c_0_pinmux {
                linux,phandle = <0x0000004f>;
                phandle = <0x0000004f>;
                mux {
                    pins = "gpio20", "gpio21";
                    function = "blsp_i2c0";
                    bias-disable;
                };
            };
            sd_0_pinmux {
                linux,phandle = <0x00000053>;
                phandle = <0x00000053>;
                sd0 {
                    pins = "gpio23";
                    function = "sdio0";
                    drive-strength = <0x0000000a>;
                };
                sd1 {
                    pins = "gpio24";
                    function = "sdio1";
                    drive-strength = <0x0000000a>;
                };
                sd2 {
                    pins = "gpio25";
                    function = "sdio2";
                    drive-strength = <0x0000000a>;
                };
                sd3 {
                    pins = "gpio26";
                    function = "sdio3";
                    drive-strength = <0x0000000a>;
                };
                sdclk {
                    pins = "gpio27";
                    function = "sdio_clk";
                    drive-strength = <0x00000010>;
                };
                sdcmd {
                    pins = "gpio28";
                    function = "sdio_cmd";
                    drive-strength = <0x0000000a>;
                };
                sd4 {
                    pins = "gpio29";
                    function = "sdio4";
                    drive-strength = <0x0000000a>;
                };
                sd5 {
                    pins = "gpio30";
                    function = "sdio5";
                    drive-strength = <0x0000000a>;
                };
                sd6 {
                    pins = "gpio31";
                    function = "sdio6";
                    drive-strength = <0x0000000a>;
                };
                sd7 {
                    pins = "gpio32";
                    function = "sdio7";
                    drive-strength = <0x0000000a>;
                    bias-disable;
                };
            };
            ts_0_pinmux {
                mux_1 {
                    pins = "gpio34";
                    output-high;
                };
                mux_2 {
                    pins = "gpio35";
                    input-enable;
                    bias-pull-up;
                };
            };
        };
        serial@78af000 {
            compatible = "qcom,msm-uartdm-v1.4", "qcom,msm-uartdm";
            reg = <0x078af000 0x00000212>;
            interrupts = <0x00000000 0x00000003 0x00000010>;
            status = "ok";
            clocks = <0x00000002 0x00000003 0x00696661 0x000002eb>;
            clock-names = "core", "iface";
            pinctrl-0 = <0x00000048>;
            pinctrl-names = "default";
        };
        serial@78b0000 {
            compatible = "qcom,msm-uartdm-v1.4", "qcom,msm-uartdm";
            reg = <0x078b0000 0x00000212>;
            interrupts = <0x00000000 0x00000003 0x00000010>;
            status = "ok";
            clocks = <0x00000002 0x00000003 0x00696661 0x000002eb>;
            clock-names = "core", "iface";
            pinctrl-0 = <0x00000049>;
            pinctrl-names = "default";
        };
        qcom,sps {
            compatible = "qcom,msm_sps_4k";
            qcom,device-type = <0x00000003>;
            qcom,pipe-attr-ee;
        };
        spi@78b5000 {
            compatible = "qcom,spi-qup-v2";
            #address-cells = <0x00000001>;
            #size-cells = <0x00000000>;
            reg-names = "spi_physical", "spi_bam_physical";
            reg = <0x078b5000 0x00000003 0x69727100 0x00000003>;
            interrupt-names = "spi_irq", "spi_bam_irq";
            interrupts = <0x00000000 0x000000ee 0x00000326 0x00000093 0x00000015 0x636f7265>;
            spi-max-frequency = <0x016e3600>;
            clocks = <0x00000002 0x00000003 0x5f636c6b 0x00000003>;
            clock-names = "core_clk", "iface_clk";
            qcom,infinite-mode = <0x00000000>;
            qcom,use-bam;
            qcom,bam-consumer-pipe-index = <0x00000004>;
            qcom,bam-producer-pipe-index = <0x00000005>;
            qcom,master-id = <0x00000000>;
            status = "ok";
            pinctrl-0 = <0x0000004a>;
            pinctrl-names = "default";
            m25p80@0 {
                #address-cells = <0x00000001>;
                #size-cells = <0x00000001>;
                reg = <0x00000000>;
                compatible = "n25q128a11";
                linux,modalias = "m25p80", "n25q128a11";
                spi-max-frequency = <0x016e3600>;
                use-default-sizes;
            };
        };
        spi@78b6000 {
            compatible = "qcom,spi-qup-v2";
            #address-cells = <0x00000001>;
            #size-cells = <0x00000000>;
            reg-names = "spi_physical", "spi_bam_physical";
            reg = <0x078b6000 0x00000003 0x69727100 0x00000003>;
            interrupt-names = "spi_irq", "spi_bam_irq";
            interrupts = <0x00000000 0x000000ee 0x00000326 0x00000093 0x00000015 0x636f7265>;
            spi-max-frequency = <0x016e3600>;
            clocks = <0x00000002 0x00000003 0x5f636c6b 0x00000003>;
            clock-names = "core_clk", "iface_clk";
            qcom,infinite-mode = <0x00000000>;
            qcom,use-bam;
            qcom,bam-consumer-pipe-index = <0x00000006>;
            qcom,bam-producer-pipe-index = <0x00000007>;
            qcom,master-id = <0x00000000>;
            status = "disabled";
        };
        qcom,nand@7980000 {
            compatible = "qcom,msm-nand";
            reg = <0x07980000 0x00000003 0x5f706879 0x00000003>;
            reg-names = "nand_phys", "bam_phys";
            interrupts = <0x00000000 0x00000008 0x00000003>;
            interrupt-names = "bam_irq";
            qcom,msm-bus,name = "qpic_nand";
            qcom,msm-bus,num-cases = <0x00000002>;
            qcom,msm-bus,num-paths = <0x00000001>;
            qcom,msm-bus,vectors-KBps = <0x0000005b 0x0000005b 0x00000003 0x655f636c 0x00000003 0x0000002b 0x00000003 0x00000001>;
            clock-names = "iface_clk", "core_clk";
            clocks = <0x00000002 0x00000003 0x00000002 0x62303030>;
            status = "ok";
        };
        tcsr@194b000 {
            compatible = "qcom,tcsr";
            reg = <0x0194b000 0x0000041c>;
            qcom,usb-hsphy-mode-select = <0x00e700e7>;
            status = "ok";
        };
        ess_tcsr@1953000 {
            compatible = "qcom,tcsr";
            reg = <0x01953000 0x00000437>;
            qcom,ess-interface-select = <0x00000000>;
        };
        ssphy@0 {
            compatible = "qca,uni-ssphy";
            reg = <0x0009a000 0x000000cc>;
            reg-names = "phy_base";
            resets = <0x00000002 0x00000458>;
            reset-names = "por_rst";
            qca,host = <0x00000001>;
            qca,emulation = <0x00000000>;
            status = "ok";
            linux,phandle = <0x0000004c>;
            phandle = <0x0000004c>;
        };
        ssphy@1 {
            compatible = "qca,dummy-ssphy";
            status = "ok";
            linux,phandle = <0x0000004e>;
            phandle = <0x0000004e>;
        };
        hsphy@a6000 {
            compatible = "qca,baldur-usb3-hsphy";
            reg = <0x000a6000 0x000000cc>;
            reg-names = "phy_base";
            resets = <0x00000002 0x00000003 0x72737400 0x00000003>;
            reset-names = "por_rst", "srif_rst";
            qca,host = <0x00000001>;
            qca,emulation = <0x00000000>;
            status = "ok";
            linux,phandle = <0x0000004b>;
            phandle = <0x0000004b>;
        };
        hsphy@a8000 {
            compatible = "qca,baldur-usb2-hsphy";
            reg = <0x000a8000 0x000000cc>;
            reg-names = "phy_base";
            resets = <0x00000002 0x00000003 0x72737400 0x00000003>;
            reset-names = "por_rst", "srif_rst";
            qca,host = <0x00000001>;
            qca,emulation = <0x00000000>;
            status = "ok";
            linux,phandle = <0x0000004d>;
            phandle = <0x0000004d>;
        };
        usb3@8a00000 {
            compatible = "qca,dwc3";
            #address-cells = <0x00000001>;
            #size-cells = <0x00000001>;
            ranges;
            reg = <0x08af8800 0x000000cc>;
            reg-names = "qscratch_base";
            clocks = <0x00000002 0x00000002 0x000002df 0x006d6f63 0x00000004 0x00000003>;
            clock-names = "master", "sleep", "mock_utmi";
            qca,host = <0x00000001>;
            status = "ok";
            dwc3@8a00000 {
                compatible = "snps,dwc3";
                reg = <0x08a00000 0x00000212>;
                interrupts = <0x00000000 0x00000008 0x00000003>;
                usb-phy = <0x0000004b 0x00000483>;
                phy-names = "usb2-phy", "usb3-phy";
                tx-fifo-resize;
                dr_mode = "host";
                usb2-susphy-quirk;
                usb2-host-discon-quirk;
                usb2-host-discon-phy-misc-reg = <0x00000024>;
                usb2-host-discon-mask = <0x00000100>;
            };
        };
        usb2@6000000 {
            compatible = "qca,dwc3";
            #address-cells = <0x00000001>;
            #size-cells = <0x00000001>;
            ranges;
            reg = <0x060f8800 0x000000cc>;
            reg-names = "qscratch_base";
            clocks = <0x00000002 0x00000002 0x000002df 0x006d6f63 0x00000004 0x00000003>;
            clock-names = "master", "sleep", "mock_utmi";
            qca,host = <0x00000001>;
            status = "ok";
            dwc3@6000000 {
                compatible = "snps,dwc3";
                reg = <0x06000000 0x00000212>;
                interrupts = <0x00000000 0x00000008 0x00000003>;
                usb-phy = <0x0000004d 0x00000483>;
                phy-names = "usb2-phy", "usb3-phy";
                tx-fifo-resize;
                dr_mode = "host";
                usb2-susphy-quirk;
                usb2-host-discon-quirk;
                usb2-host-discon-phy-misc-reg = <0x00000024>;
                usb2-host-discon-mask = <0x00000100>;
            };
        };
        rng@0x00022000 {
            compatible = "qcom,prng";
            reg = <0x00022000 0x00000093>;
            clocks = <0x00000002 0x000002df>;
            clock-names = "core";
        };
        i2c@78b7000 {
            compatible = "qcom,i2c-msm-v2";
            #address-cells = <0x00000001>;
            #size-cells = <0x00000000>;
            reg-names = "qup_phys_addr", "bam_phys_addr";
            reg = <0x078b7000 0x00000003 0x69727100 0x00000018>;
            interrupt-names = "qup_irq", "bam_irq";
            interrupts = <0x00000000 0x000000ee 0x00000093 0x00000016 0x69666163 0x6c6b0000>;
            clocks = <0x00000002 0x00000003 0x655f636c 0x00000003>;
            clock-names = "iface_clk", "core_clk";
            qcom,clk-freq-out = <0x000186a0>;
            qcom,clk-freq-in = <0x0122ae10>;
            qcom,noise-rjct-scl = <0x00000000>;
            qcom,noise-rjct-sda = <0x00000000>;
            qcom,bam-pipe-idx-cons = <0x00000008>;
            qcom,bam-pipe-idx-prod = <0x00000009>;
            qcom,master-id = <0x00000000>;
            status = "ok";
            pinctrl-0 = <0x0000004f>;
            pinctrl-1 = <0x0000004f>;
            pinctrl-names = "i2c_active", "i2c_sleep";
            qca_codec@12 {
                compatible = "qca,ipq40xx-codec";
                reg = <0x00000012>;
                status = "disabled";
            };
            lcd_ts@40 {
                compatible = "qca,gsl1680_ts";
                reg = <0x00000040>;
                status = "disabled";
            };
        };
        i2c@78b8000 {
            compatible = "qcom,i2c-msm-v2";
            #address-cells = <0x00000001>;
            #size-cells = <0x00000000>;
            reg-names = "qup_phys_addr", "bam_phys_addr";
            reg = <0x078b8000 0x00000003 0x69727100 0x00000018>;
            interrupt-names = "qup_irq", "bam_irq";
            interrupts = <0x00000000 0x000000ee 0x00000093 0x00000018 0x69666163 0x6c6b0000>;
            clocks = <0x00000002 0x00000003 0x655f636c 0x00000003>;
            clock-names = "iface_clk", "core_clk";
            qcom,clk-freq-out = <0x000186a0>;
            qcom,clk-freq-in = <0x0122ae10>;
            qcom,noise-rjct-scl = <0x00000000>;
            qcom,noise-rjct-sda = <0x00000000>;
            qcom,bam-pipe-idx-cons = <0x0000000a>;
            qcom,bam-pipe-idx-prod = <0x0000000b>;
            qcom,master-id = <0x00000000>;
            status = "disabled";
        };
        qcrypto@8e20000 {
            compatible = "qcom,qcrypto";
            reg = <0x08e20000 0x00000003 0x746f2d62 0x616d2d62>;
            reg-names = "crypto-base", "crypto-bam-base";
            interrupts = <0x00000000 0x00000004 0x00000004>;
            qcom,bam-pipe-pair = <0x00000001>;
            qcom,ce-hw-instance = <0x00000000>;
            qcom,ce-hw-shared = <0x00000001>;
            qcom,ce-device = <0x00000000>;
            qcom,ce-opp-freq = <0x07735940>;
            clocks = <0x00000002 0x00000002 0x000002df 0x5f636c6b 0x00000003 0x00000002>;
            clock-names = "core_clk", "bus_clk", "iface_clk";
            status = "ok";
        };
        qcedev@8e20000 {
            compatible = "qcom,qcedev";
            reg = <0x08e20000 0x00000003 0x746f2d62 0x616d2d62>;
            reg-names = "crypto-base", "crypto-bam-base";
            interrupts = <0x00000000 0x00000004 0x00000004>;
            qcom,bam-pipe-pair = <0x00000001>;
            qcom,ce-hw-instance = <0x00000000>;
            qcom,ce-hw-shared = <0x00000001>;
            qcom,ce-device = <0x00000000>;
            qcom,ce-opp-freq = <0x07735940>;
            clocks = <0x00000002 0x00000002 0x000002df 0x5f636c6b 0x00000003 0x00000002>;
            clock-names = "core_clk", "bus_clk", "iface_clk";
            status = "ok";
        };
        tcsr@1949000 {
            compatible = "qcom,tcsr";
            reg = <0x01949000 0x000005dd>;
            qcom,wifi_glb_cfg = <0x41000000>;
        };
        tcsr@1957000 {
            compatible = "qcom,tcsr";
            reg = <0x01957000 0x000005ef>;
            qcom,wifi_noc_memtype_m0_m2 = <0x02222222>;
        };
        wifi@a000000 {
            compatible = "qca,wifi-ipq40xx";
            reg = <0x0a000000 0x0000060b>;
            core-id = <0x00000000>;
            resets = <0x00000002 0x00000002 0x00000002 0x00000003 0x5f637075 0x6164696f 0x6164696f 0x6164696f 0x6f72655f 0x72655f63 0x00000093 0x0000003b>;
            reset-names = "wifi_cpu_init", "wifi_radio_srif", "wifi_radio_warm", "wifi_radio_cold", "wifi_core_warm", "wifi_core_cold";
            clocks = <0x00000002 0x00000002 0x000002df 0x64007769 0x77696669 0x00000003>;
            clock-names = "wifi_wcss_cmd", "wifi_wcss_ref", "wifi_wcss_rtc";
            interrupts = <0x00000000 0x00000021 0x00000001 0x00000000 0x00000025 0x00000001 0x00000000 0x00000029 0x00000001 0x00000000 0x0000002d 0x00000001 0x00000000 0x0000005d 0x31006d73 0x006d7369 0x6d736938 0x6d736931 0x33006d73 0x67616379 0x0000020b 0x00000613 0x00000620 0x0000062d 0x0000063a 0x77696669 0x00000003 0x77696669 0x00000003 0x00200000 0x00000001 0x00000002 0x00000002 0x00000002 0x00000003 0x5f637075 0x6164696f 0x6164696f 0x6164696f 0x6f72655f 0x72655f63 0x00000093 0x0000003e 0x0000002a 0x735f636d 0x72656600 0x63000000 0x00000000 0x00000031 0x00000001 0x00000000>;
            interrupt-names = "msi0", "msi1", "msi2", "msi3", "msi4", "msi5", "msi6", "msi7", "msi8", "msi9", "msi10", "msi11", "msi12", "msi13", "msi14", "msi15", "legacy";
            status = "ok";
            qca,msi_addr = <0x0b006040>;
            qca,msi_base = <0x00000040>;
            wifi_led_num = <0x00000002>;
            wifi_led_source = <0x00000000>;
        };
        wifi@a800000 {
            compatible = "qca,wifi-ipq40xx";
            reg = <0x0a800000 0x0000060b>;
            core-id = <0x00000001>;
            resets = <0x00000002 0x00000002 0x00000002 0x00000003 0x5f637075 0x6164696f 0x6164696f 0x6164696f 0x6f72655f 0x72655f63 0x00000093 0x0000003e>;
            reset-names = "wifi_cpu_init", "wifi_radio_srif", "wifi_radio_warm", "wifi_radio_cold", "wifi_core_warm", "wifi_core_cold";
            clocks = <0x00000002 0x00000002 0x000002df 0x64007769 0x77696669 0x00000003>;
            clock-names = "wifi_wcss_cmd", "wifi_wcss_ref", "wifi_wcss_rtc";
            interrupts = <0x00000000 0x00000031 0x00000001 0x00000000 0x00000035 0x00000001 0x00000000 0x00000039 0x00000001 0x00000000 0x0000003d 0x00000001 0x00000000 0x0000005d 0x31006d73 0x006d7369 0x6d736938 0x6d736931 0x33006d73 0x67616379 0x0000020b 0x00000613 0x00000620 0x0000062d 0x0000063a 0x65646d61 0x00000003 0x2c657373 0x00000008 0x00000003 0x00000003 0x00000003 0x00000003 0x00000180 0x00000001 0x00000000 0x00000044 0x00000001 0x00000000 0x00000048 0x00000001 0x00000000 0x0000004c 0x00000001 0x00000000 0x00000050 0x00000001 0x00000000 0x000000f3 0x00000001 0x00000000>;
            interrupt-names = "msi0", "msi1", "msi2", "msi3", "msi4", "msi5", "msi6", "msi7", "msi8", "msi9", "msi10", "msi11", "msi12", "msi13", "msi14", "msi15", "legacy";
            status = "ok";
            qca,msi_addr = <0x0b006040>;
            qca,msi_base = <0x00000050>;
            wifi_led_num = <0x00000001>;
            wifi_led_source = <0x00000002>;
        };
        edma@c080000 {
            compatible = "qcom,ess-edma";
            reg = <0x0c080000 0x0000064a>;
            qcom,page-mode = <0x00000000>;
            qcom,rx_head_buf_size = <0x00000604>;
            qcom,num_gmac = <0x00000002>;
            qcom,mdio_supported;
            interrupts = <0x00000000 0x00000042 0x00000001 0x00000000 0x00000046 0x00000001 0x00000000 0x0000004a 0x00000001 0x00000000 0x0000004e 0x00000001 0x00000000 0x000000f1 0x00000001 0x00000000 0x000000f5 0x00000001 0x00000000 0x000000f9 0x00000001 0x00000000 0x000000fd 0x00000001 0x00000001 0x00000006 0x00000003 0x00000003 0x00000003 0x00000003 0x00000003 0x00000020 0x31000000 0x00000000 0x000006ee 0x00000002 0x65403830 0x00000021 0x65000000 0x00000000 0x00000001 0x00080000 0x40000000 0x40100000 0x40300000 0x000000cc 0x636f7265 0x6f006261 0x00000000 0x0000002c 0x00000212 0x00000003 0x00000007 0x0000000b 0x000001ed 0x00000710 0x00000723 0x0000008d 0x00000000 0x00000001 0x00000003 0x00000000 0x00000091 0x00000000 0x00000001 0x00000007 0x00000000 0x00000095 0x00000000 0x00000001 0x0000000b 0x00000000 0x696e745f 0x745f6200 0x696e745f 0x706d655f 0x6c735f65 0x65676163 0x6e6b5f75 0x6e6b5f64 0x67655f66 0x616b6500 0x0000000a 0x00000002 0x00000002 0x000002df 0x68625f63 0x74725f61 0x305f736c 0x00000003 0x00000000 0x00000451 0x0000001b 0x00000019 0x00000017 0x00000015>;
            gmac0 {
                local-mac-address = [00 00 00 00 00 00];
                qcom,phy_mdio_addr = <0x00000004>;
                qcom,poll_required = <0x00000001>;
                qcom,forced_speed = <0x000003e8>;
                qcom,forced_duplex = <0x00000001>;
                vlan_tag = <0x00000002 0x676d6163>;
            };
            gmac1 {
                local-mac-address = [00 00 00 00 00 00];
                vlan_tag = <0x00000001 0x00000001>;
            };
        };
        qcom,pcie@80000 {
            compatible = "qcom,msm_pcie";
            cell-index = <0x00000000>;
            qcom,ctrl-amt = <0x00000001>;
            reg = <0x00080000 0x40000000 0x40100000 0x40300000 0x000000cc 0x636f7265 0x6f006261 0x00000000 0x0000002c 0x00000212 0x00000003 0x00000007 0x0000000b 0x000001ed>;
            reg-names = "parf", "phy", "dm_core", "elbi", "conf", "io", "bars";
            #address-cells = <0x00000000>;
            interrupt-parent = <0x00000050>;
            interrupts = <0x00000000 0x00000004 0x00000008 0x0000000c 0x00000001 0xffffffff 0x00000000 0x00000000 0x0000008e 0x00000000 0x00000001 0x00000004 0x00000000>;
            #interrupt-cells = <0x00000001>;
            interrupt-map-mask = <0xffffffff>;
            interrupt-map = <0x00000000 0x00000000 0x0000008e 0x00000000 0x00000001 0x00000004 0x00000000 0x00000092 0x00000000 0x00000001 0x00000008 0x00000000 0x00000096 0x00000000 0x00000001 0x00000003 0x6d736900 0x696e745f 0x706c735f 0x6c656761 0x72720069 0x7900696e 0x7000696e 0x6f776e00 0x6c757368 0x00000003 0x00000003 0x00000026 0x00000028 0x70636965 0x6c6b0070 0x78695f63 0x765f6178 0x0000000c 0x00000000 0x00000002 0x00000002 0x00000002 0x00000002 0x00000002 0x00000002 0x00000003 0x5f727374 0x70636965 0x72657300 0x655f6172 0x6178695f 0x73007063 0x5f787075 0x73745f70 0x00706369 0x65730070 0x6d5f7374 0x69655f72 0x6b795f61 0x5f707772 0x73745f61 0x7273745f 0x00000000 0x6f6b0000>;
            interrupt-names = "int_msi", "int_a", "int_b", "int_c", "int_d", "int_pls_pme", "int_pme_legacy", "int_pls_err", "int_aer_legacy", "int_pls_link_up", "int_pls_link_down", "int_bridge_flush_n", "int_wake";
            qcom,ep-latency = <0x0000000a>;
            clocks = <0x00000002 0x00000002 0x000002df 0x68625f63 0x74725f61 0x305f736c>;
            clock-names = "pcie_0_cfg_ahb_clk", "pcie_0_mstr_axi_clk", "pcie_0_slv_axi_clk";
            max-clock-frequency-hz = <0x00000000 0x00000060 0x00000002>;
            resets = <0x00000002 0x00000002 0x00000002 0x00000002 0x00000002 0x00000002 0x00000003 0x5f727374 0x70636965 0x72657300 0x655f6172 0x6178695f 0x73007063 0x5f787075 0x73745f70 0x00706369 0x65730070 0x6d5f7374 0x69655f72 0x6b795f61 0x5f707772 0x73745f61 0x7273745f 0x00000000>;
            reset-names = "pcie_rst_axi_m_ares", "pcie_rst_axi_s_ares", "pcie_rst_pipe_ares", "pcie_rst_axi_m_vmidmt_ares", "pcie_rst_axi_s_xpu_ares", "pcie_rst_parf_xpu_ares", "pcie_rst_phy_ares", "pcie_rst_axi_m_sticky_ares", "pcie_rst_pipe_sticky_ares", "pcie_rst_pwr_ares", "pcie_rst_ahb_res", "pcie_rst_phy_ahb_ares";
            status = "ok";
            perst-gpio = <0x00000051 0x0000000c 0x00000000>;
            wake-gpio = <0x00000051 0x0000000c 0x00000000>;
            clkreq-gpio = <0x00000051 0x00000004 0x00000004>;
            linux,phandle = <0x00000050>;
            phandle = <0x00000050>;
        };
        pwm {
            compatible = "qca,ipq4019-pwm";
            clocks = <0x00000002 0x000002df>;
            clock-names = "core";
            pwm-base-index = <0x00000000>;
            used-pwm-indices = <0x00000001 0x00000003 0x626c6564 0x6c656463>;
            status = "disabled";
        };
        ledc@1937000 {
            compatible = "qca,ledc";
            reg = <0x01937000 0x000000cc>;
            reg-names = "ledc_base_addr";
            qcom,tcsr_ledc_values = <0x00320193 0x00000000 0x007d0010 0x00000003 0x00000003 0x00000003 0x00000003 0x00000003 0x756c7400 0x00000003 0x636f7274 0x00000003>;
            qcom,ledc_blink_indices_cnt = <0x00000000>;
            qcom,ledc_blink_indices = <0x00000000>;
            status = "ok";
            pinctrl-0 = <0x00000052>;
            pinctrl-names = "default";
        };
        pmu {
            compatible = "arm,cortex-a7-pmu";
            interrupts = <0x00000001 0x00000001 0x30000000>;
        };
        sdhci@7824000 {
            compatible = "qcom,sdhci-msm-v4";
            reg = <0x07824900 0x00000003 0x0000007b 0x00000000>;
            interrupts = <0x00000000 0x0000008a 0x000007e3 0x00000093 0x0000002d 0x636f7265>;
            bus-width = <0x00000008>;
            clocks = <0x00000002 0x00000003 0x00696661 0x0000020b>;
            clock-names = "core", "iface";
            status = "ok";
            pinctrl-0 = <0x00000053>;
            pinctrl-names = "default";
            vqmmc-supply = <0x00000054>;
            cd-gpios = <0x00000051 0x0000000c 0x00000001>;
            sd-ldo-gpios = <0x00000051 0x00000001 0x30303030>;
        };
        ess-switch@c000000 {
            compatible = "qcom,ess-switch";
            reg = <0x0c000000 0x00000810>;
            switch_access_mode = "local bus";
            resets = <0x00000002 0x00000002 0x00000002 0x00000003 0x72737400 0x5f646973 0x6b5f6469 0x6c6b5f64 0x636c6b5f 0x5f636c6b 0x00000008 0x00000003>;
            reset-names = "ess_rst", "ess_mac1_clk_dis", "ess_mac2_clk_dis", "ess_mac3_clk_dis", "ess_mac4_clk_dis", "ess_mac5_clk_dis";
            clocks = <0x00000002 0x000002df>;
            clock-names = "ess_clk";
            switch_cpu_bmp = <0x00000001>;
            switch_lan_bmp = <0x0000001e>;
            switch_wan_bmp = <0x00000020>;
            switch_mac_mode = <0x00000000>;
            switch_initvlas = <0x0000007c 0x736f7572>;
            led_source@0 {
                source = <0x00000001>;
                mode = "normal";
                speed = "all";
                freq = "auto";
            };
            led_source@1 {
                source = <0x00000004>;
                mode = "normal";
                speed = "all";
                freq = "auto";
            };
            led_source@2 {
                source = <0x00000007>;
                mode = "normal";
                speed = "all";
                freq = "auto";
            };
            led_source@3 {
                source = <0x0000000a>;
                mode = "normal";
                speed = "all";
                freq = "auto";
            };
            led_source@4 {
                source = <0x0000000d>;
                mode = "normal";
                speed = "all";
                freq = "auto";
            };
        };
        ess-psgmii@98000 {
            compatible = "qcom,ess-psgmii";
            reg = <0x00098000 0x00000870>;
            psgmii_access_mode = "local bus";
            resets = <0x00000002 0x00000458>;
            reset-names = "psgmii_rst";
        };
        mdio@90000 {
            #address-cells = <0x00000001>;
            #size-cells = <0x00000001>;
            compatible = "qcom,ipq40xx-mdio";
            reg = <0x00090000 0x726e6574>;
            ethernet-phy@0 {
                reg = <0x00000000>;
            };
            ethernet-phy@1 {
                reg = <0x00000001>;
            };
            ethernet-phy@2 {
                reg = <0x00000002>;
            };
            ethernet-phy@3 {
                reg = <0x00000003>;
            };
            ethernet-phy@4 {
                reg = <0x00000004>;
            };
        };
        qca,scm_restart_reason {
            compatible = "qca,scm_restart_reason";
        };
        cpu_freq_ipq40xx {
            compatible = "qca,ipq40xx_freq";
            clock-latency = <0x000186a0>;
            qcom,cpufreq-table = <0x0000bb80 0x00000002 0x30303030 0x00000021>;
        };
        uart@78b0000 {
            compatible = "qcom,msm-hsuart-v14";
            reg = <0x078b0000 0x00000003 0x5f6d656d 0x00000003>;
            reg-names = "core_mem", "bam_mem";
            interrupt-names = "core_irq", "bam_irq";
            #address-cells = <0x00000000>;
            interrupt-parent = <0x00000055>;
            interrupts = <0x00000000 0x00000004 0x00000004>;
            #interrupt-cells = <0x00000001>;
            interrupt-map-mask = <0xffffffff>;
            interrupt-map = <0x00000000 0x00000000 0x000000ee 0x000008a4 0x000008be 0x00000392 0x00000093 0x0000001b 0x69666163 0x6c6b0000>;
            qcom,bam-tx-ep-pipe-index = <0x00000002>;
            qcom,bam-rx-ep-pipe-index = <0x00000003>;
            qcom,master-id = <0x00000056>;
            clocks = <0x00000002 0x00000003 0x655f636c 0x00000003>;
            clock-names = "iface_clk", "core_clk";
            status = "disabled";
            pinctrl-0 = <0x00000056>;
            pinctrl-1 = <0x00000056>;
            pinctrl-names = "default", "sleep";
            linux,phandle = <0x00000055>;
            phandle = <0x00000055>;
        };
        regulator@0 {
            compatible = "qcom,regulator-ipq40xx";
            regulator-name = "SD0 VccQ";
            regulator-min-microvolt = <0x001b7740>;
            regulator-max-microvolt = <0x002dc6c0>;
            states = <0x002dc6c0 0x00000003 0x00000004 0x00000003>;
            reg = <0x01948000 0x000004fc>;
            mask = <0x00000003>;
            linux,phandle = <0x00000054>;
            phandle = <0x00000054>;
        };
        gpio_keys {
            compatible = "gpio-keys";
            button@1 {
                label = "wps";
                linux,code = <0x00000211>;
                gpios = <0x00000051 0x00000004 0x00000002>;
                linux,input-type = <0x00000001>;
            };
        };
        qcom,msm_qpic@7980000 {
            compatible = "qcom,mdss_qpic";
            reg = <0x07980000 0x000000cc>;
            reg-names = "qpic_base";
            interrupt-names = "lcdc_irq", "bam_irq";
            interrupts = <0x00000000 0x00000065 0x000003c2 0x00000003 0x00000003 0x00000003>;
            qcom,msm-bus,name = "mdss_qpic";
            qcom,msm-bus,num-cases = <0x00000002>;
            qcom,msm-bus,num-paths = <0x00000001>;
            qcom,msm-bus,vectors-KBps = <0x0000005b 0x0000005b 0x00000003 0x00000002 0x735f6c63 0x00000000 0x71636f6d 0x616e656c>;
            status = "ok";
        };
        qcom,mdss_lcd_qpic_panel {
            compatible = "qcom,mdss-qpic-panel";
            label = "qpic lcd panel";
            qcom,mdss-pan-res = <0x00000320 0x0000094c>;
            qcom,mdss-pan-bpp = <0x00000012>;
            qcom,refresh_rate = <0x0000003c>;
            status = "ok";
        };
    };
    reserved-memory {
        #address-cells = <0x00000001>;
        #size-cells = <0x00000001>;
        ranges;
        rsvd1@87000000 {
            reg = <0x87000000 0x00000970>;
            no-map;
        };
        wifi_dump@87500000 {
            reg = <0x87500000 0x00000970>;
            no-map;
        };
        rsvd2@87B00000 {
            reg = <0x87b00000 0x00000970>;
            no-map;
        };
    };
};
